# f28p65x_nmi_intrupt_regs register map
Vendor: Texas Instruments
Peripheral module from a debugger description file (folder C2000).
Address unit: 16 bits
Registers are 16-bit, read-write, no defined reset value unless marked. A register's access mark holds for its fields unless they carry their own. Offsets are as the file gives them; lines under a group give offsets from that group; [hi:lo] are bit positions; {n}, {i} and the like mark numbered series; 'fields as' and 'values as' point back to an identical list; <NAME> marks a mode.

## NMI_INTRUPT_REGS — NMI INTRUPT Registers
0x00 NMICFG — NMI Configuration Register
  [0] NMIE — Global NMI Enable
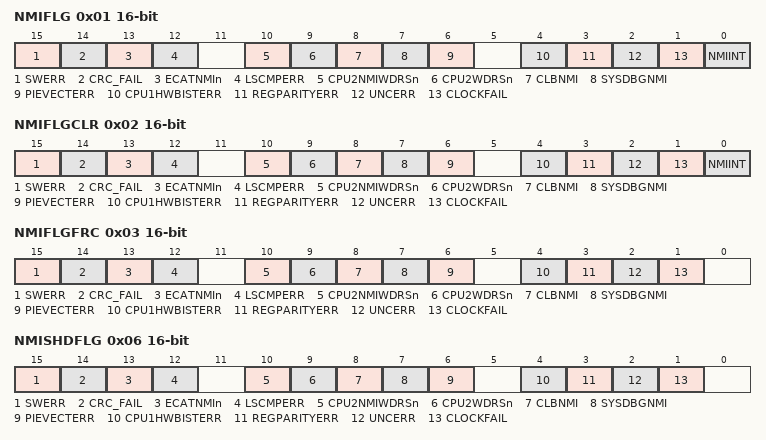
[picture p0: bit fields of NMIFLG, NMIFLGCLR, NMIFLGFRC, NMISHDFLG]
0x01 NMIFLG ro — NMI Flag Register (SYSRsn Clear)
  [15] SWERR — SW Error Force NMI Flag
  [14] CRC_FAIL — BGCRC calculation failed.
  [13] ECATNMIn — EtherCAT NMI Flag
  [12] LSCMPERR — Lockstep Compare Error
  [10] CPU2NMIWDRSn — CPU2 NMIWDRSn Reset Indication Flag
  [9] CPU2WDRSn — CPU2 WDRSn Reset Indication Flag
  [8] CLBNMI — Reconfigurable Logic NMI Flag
  [7] SYSDBGNMI — System Debug Module NMI Flag
  [6] PIEVECTERR — PIE Vector Fetch Error Flag
  [4] CPU1HWBISTERR — HW BIST Error NMI Flag
  [3] REGPARITYERR — Register parity error
  [2] UNCERR — Flash/RAM/ROM Uncorrectable Error NMI Flag
  [1] CLOCKFAIL — Clock Fail Interrupt Flag
  [0] NMIINT — NMI Interrupt Flag
0x02 NMIFLGCLR — NMI Flag Clear Register
  [15] SWERR — SW Error Force NMI Flag Clear
  [14] CRC_FAIL — BGCRC calculation Flag Clear
  [13] ECATNMIn — EtherCAT NMI Flag Clear
  [12] LSCMPERR — Lockstep Compare Error Clear
  [10] CPU2NMIWDRSn — CPU2 NMIWDRSn Reset Indication Flag Clear
  [9] CPU2WDRSn — CPU2 WDRSn Reset Indication Flag Clear
  [8] CLBNMI — Reconfigurable Logic NMI Flag Clear
  [7] SYSDBGNMI — System Debug Module NMI Flag Clear
  [6] PIEVECTERR — PIE Vector Fetch Error Flag Clear
  [4] CPU1HWBISTERR — HW BIST Error NMI Flag Clear
  [3] REGPARITYERR — Register parity error Clear
  [2] UNCERR — Flash/RAM/ROM Uncorrectable Error NMI Flag Clear
  [1] CLOCKFAIL — Clock Fail Interrupt Flag Clear
  [0] NMIINT — NMI Interrupt Flag Clear
0x03 NMIFLGFRC — NMI Flag Force Register
  [15] SWERR — SW Error Force NMI Flag Force
  [14] CRC_FAIL — BGCRC calculation Flag Force
  [13] ECATNMIn — EtherCAT NMI Flag Force
  [12] LSCMPERR — Lockstep Compare Error Force
  [10] CPU2NMIWDRSn — CPU2 NMIWDRSn Reset Indication Flag Force
  [9] CPU2WDRSn — CPU2 WDRSn Reset Indication Flag Force
  [8] CLBNMI — Reconfigurable Logic NMI Flag Force
  [7] SYSDBGNMI — System Debug Module NMI Flag Force
  [6] PIEVECTERR — PIE Vector Fetch Error Flag Force
  [4] CPU1HWBISTERR — HW BIST Error NMI Flag Force
  [3] REGPARITYERR — Register parity error Force
  [2] UNCERR — Flash/RAM/ROM Uncorrectable Error NMI Flag Force
  [1] CLOCKFAIL — Clock Fail Interrupt Flag Force
0x04 NMIWDCNT ro — NMI Watchdog Counter Register
  [15:0] NMIWDCNT — NMI Watchdog Counter
0x05 NMIWDPRD — NMI Watchdog Period Register
  [15:0] NMIWDPRD — NMI Watchdog Period
0x06 NMISHDFLG ro — NMI Shadow Flag Register
  [15] SWERR — SW Error Force NMI Flag
  [14] CRC_FAIL — Shadow BGCRC calculation failed flag
  [13] ECATNMIn — Shadow EtherCAT NMI Flag
  [12] LSCMPERR — ShadowLockstep Compare Error
  [10] CPU2NMIWDRSn — Shadow CPU2 NMIWDRSn Reset Indication Flag
  [9] CPU2WDRSn — Shadow CPU2 WDRSn Reset Indication Flag
  [8] CLBNMI — Shadow Reconfigurable Logic NMI Flag
  [7] SYSDBGNMI — Shadow System Debug Module NMI Flag
  [6] PIEVECTERR — Shadow PIE Vector Fetch Error Flag
  [4] CPU1HWBISTERR — Shadow HW BIST Error NMI Flag
  [3] REGPARITYERR — Shadow Register parity error
  [2] UNCERR — Shadow Flash/RAM/ROM Uncorrectable Error NMI Flag
  [1] CLOCKFAIL — Shadow Clock Fail Interrupt Flag
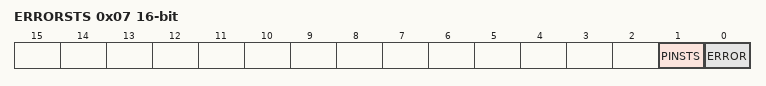
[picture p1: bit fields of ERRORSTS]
0x07 ERRORSTS ro — Error pin status (One copy of same register, readable from both CPU1 and CPU2 )
  [1] PINSTS — Error pin status.
  [0] ERROR — Error flag.
0x08 ERRORSTSCLR — ERRORSTS clear register
  [0] ERROR — ERRORFLG.ERROR clear bit
0x09 ERRORSTSFRC — ERRORSTS force register
  [0] ERROR — ERRORSTS.ERROR pin force.
0x0A ERRORCTL — Error pin control register (CPU2 can only read the register, CPU1 can R/W)
  [0] ERRORPOLSEL — ERROR pin polarity select
0x0B ERRORLOCK — Lock register to Error pin registers. (Available only for CPU1)
  [0] ERRORCTL — ERRORCTL Lock bit
